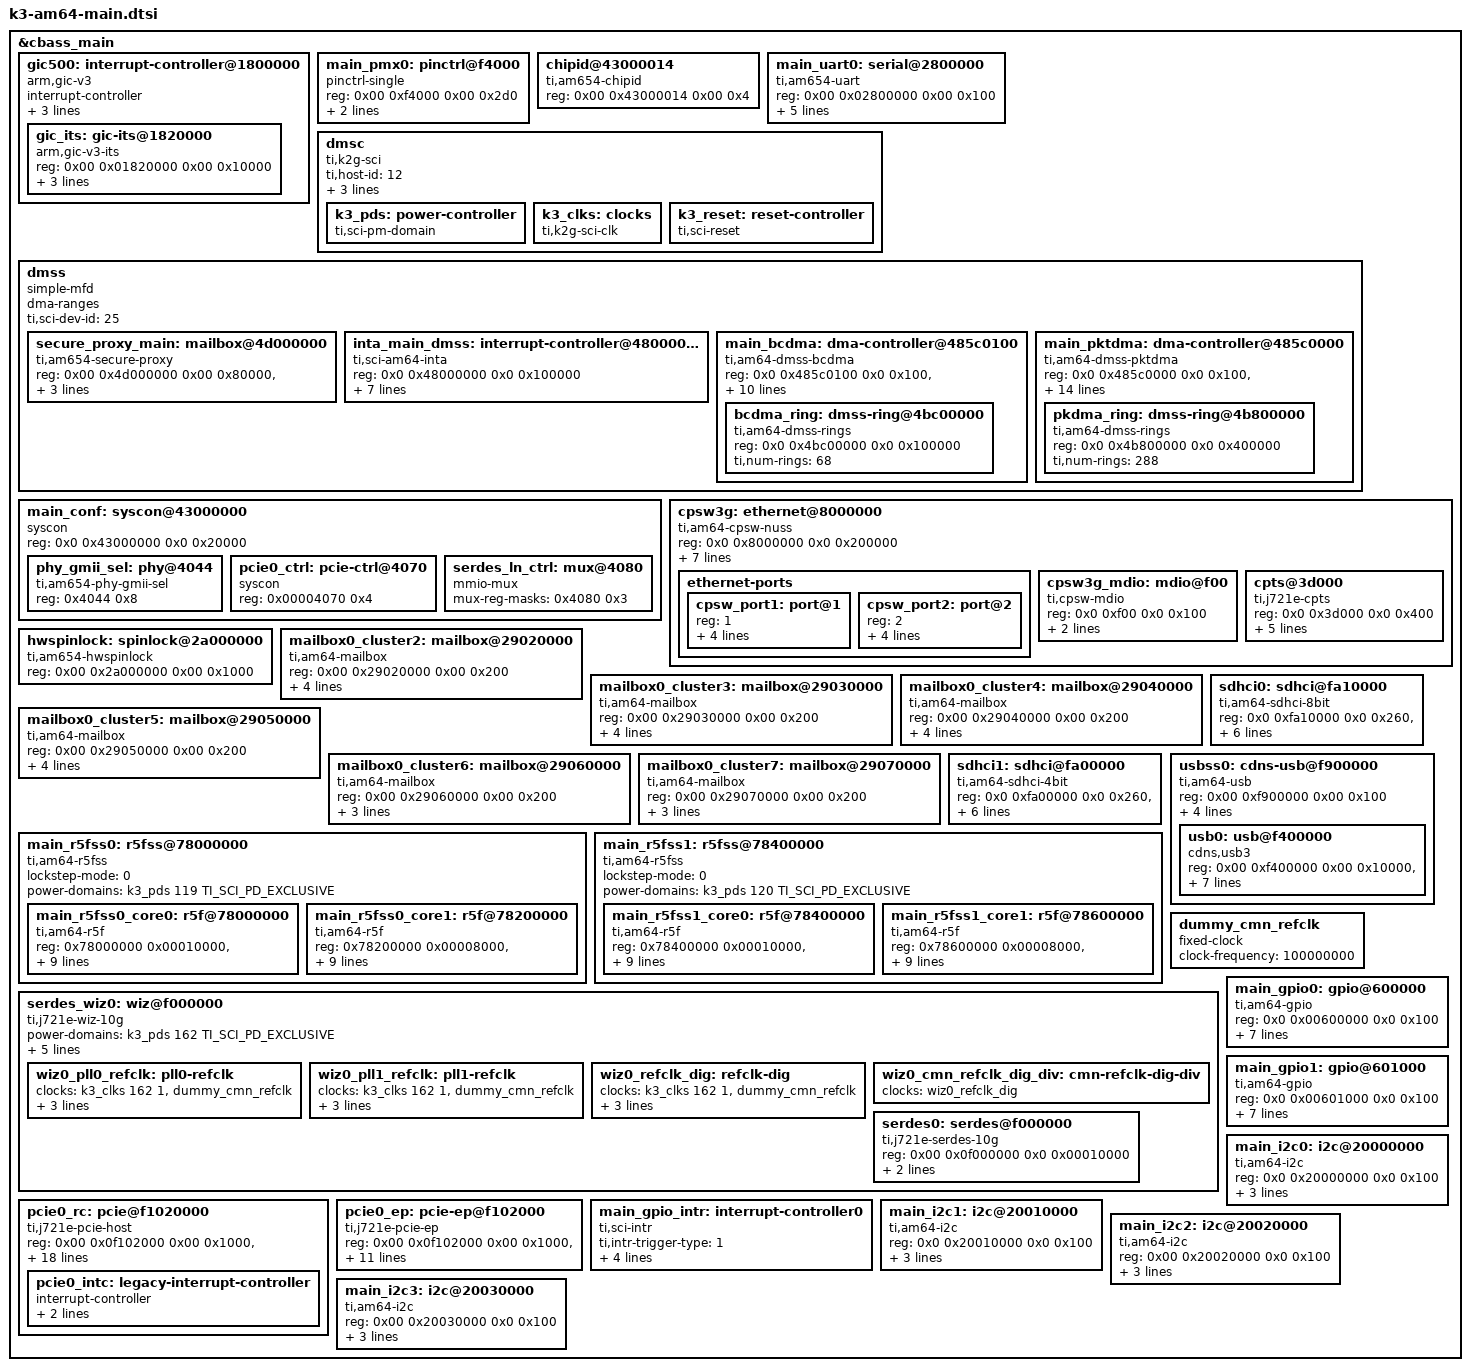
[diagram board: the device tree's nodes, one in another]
// SPDX-License-Identifier: GPL-2.0
/*
 * Device Tree Source for AM64 SoC Family Main Domain peripherals
 *
 * Copyright (C) 2019-2020 Texas Instruments Incorporated - https://www.ti.com/
 */

&cbass_main {
	gic500: interrupt-controller@1800000 {
		compatible = "arm,gic-v3";
		#address-cells = <2>;
		#size-cells = <2>;
		ranges;
		#interrupt-cells = <3>;
		interrupt-controller;
		reg = <0x00 0x01800000 0x00 0x10000>,	/* GICD */
		      <0x00 0x01840000 0x00 0xC0000>;	/* GICR */
		/*
		 * vcpumntirq:
		 * virtual CPU interface maintenance interrupt
		 */
		interrupts = <GIC_PPI 9 IRQ_TYPE_LEVEL_HIGH>;

		gic_its: gic-its@1820000 {
			compatible = "arm,gic-v3-its";
			reg = <0x00 0x01820000 0x00 0x10000>;
			socionext,synquacer-pre-its = <0x1000000 0x400000>;
			msi-controller;
			#msi-cells = <1>;
		};
	};

	main_pmx0: pinctrl@f4000 {
		compatible = "pinctrl-single";
		reg = <0x00 0xf4000 0x00 0x2d0>;
		#pinctrl-cells = <1>;
		pinctrl-single,register-width = <32>;
		pinctrl-single,function-mask = <0xffffffff>;
	};

	chipid@43000014 {
		compatible = "ti,am654-chipid";
		reg = <0x00 0x43000014 0x00 0x4>;
	};

	main_uart0: serial@2800000 {
		compatible = "ti,am654-uart";
		reg = <0x00 0x02800000 0x00 0x100>;
		reg-shift = <2>;
		reg-io-width = <4>;
		interrupts = <GIC_SPI 178 IRQ_TYPE_LEVEL_HIGH>;
		clock-frequency = <48000000>;
		current-speed = <115200>;
	};

	dmsc: dmsc {
		compatible = "ti,k2g-sci";
		ti,host-id = <12>;
		mbox-names = "rx", "tx";
		mboxes= <&secure_proxy_main 12>,
			<&secure_proxy_main 13>;

		k3_pds: power-controller {
			compatible = "ti,sci-pm-domain";
			#power-domain-cells = <2>;
		};

		k3_clks: clocks {
			compatible = "ti,k2g-sci-clk";
			#clock-cells = <2>;
		};

		k3_reset: reset-controller {
			compatible = "ti,sci-reset";
			#reset-cells = <2>;
		};
	};

	dmss {
		compatible = "simple-mfd";
		#address-cells = <2>;
		#size-cells = <2>;
		dma-ranges;
		ranges;

		ti,sci-dev-id = <25>;

		secure_proxy_main: mailbox@4d000000 {
			compatible = "ti,am654-secure-proxy";
			#mbox-cells = <1>;
			reg-names = "target_data", "rt", "scfg";
			reg = <0x00 0x4d000000 0x00 0x80000>,
			      <0x00 0x4a600000 0x00 0x80000>,
			      <0x00 0x4a400000 0x00 0x80000>;
			interrupt-names = "rx_012";
			interrupts = <GIC_SPI 34 IRQ_TYPE_LEVEL_HIGH>;
		};

		inta_main_dmss: interrupt-controller@48000000 {
			compatible = "ti,sci-am64-inta";
			reg = <0x0 0x48000000 0x0 0x100000>;
			interrupt-controller;
			interrupt-parent = <&gic500>;
			msi-controller;
			ti,sci = <&dmsc>;
			ti,sci-dev-id = <28>;
			ti,dev-ids-for-unmapped = <26>, <30>;
			ti,interrupt-ranges = <4 68 36>;
		};

		main_bcdma: dma-controller@485c0100 {
			compatible = "ti,am64-dmss-bcdma";
			#address-cells = <2>;
			#size-cells = <2>;
			ranges;

			reg =	<0x0 0x485c0100 0x0 0x100>,
				<0x0 0x4c000000 0x0 0x20000>,
				<0x0 0x4a820000 0x0 0x20000>,
				<0x0 0x4aa40000 0x0 0x20000>;
			reg-names = "gcfg", "bchanrt", "rchanrt", "tchanrt";
			msi-parent = <&inta_main_dmss>;
			#dma-cells = <2>;

			ti,sci = <&dmsc>;
			ti,sci-dev-id = <26>;
			ti,ringacc = <&bcdma_ring>;

			ti,sci-rm-range-bchan = <0x20>; /* BLOCK_COPY_CHAN */
			ti,sci-rm-range-rchan = <0x21>; /* SPLIT_TR_RX_CHAN */
			ti,sci-rm-range-tchan = <0x22>; /* SPLIT_TR_TX_CHAN */

			bcdma_ring: dmss-ring@4bc00000 {
				compatible = "ti,am64-dmss-rings";
				reg =	<0x0 0x4bc00000 0x0 0x100000>;
				reg-names = "rt";
				ti,num-rings = <68>;
			};
		};

		main_pktdma: dma-controller@485c0000 {
			compatible = "ti,am64-dmss-pktdma";
			#address-cells = <2>;
			#size-cells = <2>;
			ranges;

			reg =	<0x0 0x485c0000 0x0 0x100>,
				<0x0 0x4a800000 0x0 0x20000>,
				<0x0 0x4aa00000 0x0 0x40000>;
			reg-names = "gcfg", "rchanrt", "tchanrt";
			msi-parent = <&inta_main_dmss>;
			#dma-cells = <2>;

			ti,sci = <&dmsc>;
			ti,sci-dev-id = <30>;
			ti,ringacc = <&pkdma_ring>;

			ti,sci-rm-range-tchan = <0x23>, /* UNMAPPED_TX_CHAN */
						<0x24>, /* CPSW_TX_CHAN */
						<0x25>, /* SAUL_TX_0_CHAN */
						<0x26>, /* SAUL_TX_1_CHAN */
						<0x27>, /* ICSSG_0_TX_CHAN */
						<0x28>; /* ICSSG_1_TX_CHAN */
			ti,sci-rm-range-tflow = <0x10>, /* RING_UNMAPPED_TX_CHAN */
						<0x11>, /* RING_CPSW_TX_CHAN */
						<0x12>, /* RING_SAUL_TX_0_CHAN */
						<0x13>, /* RING_SAUL_TX_1_CHAN */
						<0x14>, /* RING_ICSSG_0_TX_CHAN */
						<0x15>; /* RING_ICSSG_1_TX_CHAN */
			ti,sci-rm-range-rchan = <0x29>, /* UNMAPPED_RX_CHAN */
						<0x2b>, /* CPSW_RX_CHAN */
						<0x2d>, /* SAUL_RX_0_CHAN */
						<0x2f>, /* SAUL_RX_1_CHAN */
						<0x31>, /* SAUL_RX_2_CHAN */
						<0x33>, /* SAUL_RX_3_CHAN */
						<0x35>, /* ICSSG_0_RX_CHAN */
						<0x37>; /* ICSSG_1_RX_CHAN */
			ti,sci-rm-range-rflow = <0x2a>, /* FLOW_UNMAPPED_RX_CHAN */
						<0x2c>, /* FLOW_CPSW_RX_CHAN */
						<0x2e>, /* FLOW_SAUL_RX_0/1_CHAN */
						<0x32>, /* FLOW_SAUL_RX_2/3_CHAN */
						<0x36>, /* FLOW_ICSSG_0_RX_CHAN */
						<0x38>; /* FLOW_ICSSG_1_RX_CHAN */

			pkdma_ring: dmss-ring@4b800000 {
				compatible = "ti,am64-dmss-rings";
				reg =	<0x0 0x4b800000 0x0 0x400000>;
				reg-names = "rt";
				ti,num-rings = <288>;
			};
		};
	};

	main_conf: syscon@43000000 {
		compatible = "syscon", "simple-mfd";
		reg = <0x0 0x43000000 0x0 0x20000>;
		#address-cells = <1>;
		#size-cells = <1>;
		ranges = <0x0 0x0 0x43000000 0x20000>;

		phy_gmii_sel: phy@4044 {
			compatible = "ti,am654-phy-gmii-sel";
			reg = <0x4044 0x8>;
			#phy-cells = <1>;
		};

		pcie0_ctrl: pcie-ctrl@4070 {
			compatible = "syscon";
			reg = <0x00004070 0x4>;
		};

		serdes_ln_ctrl: mux@4080 {
			compatible = "mmio-mux";
			#mux-control-cells = <1>;
			mux-reg-masks = <0x4080 0x3>; /* SERDES0 lane0 select */
		};
	};


	cpsw3g: ethernet@8000000 {
		compatible = "ti,am64-cpsw-nuss";
		#address-cells = <2>;
		#size-cells = <2>;
		reg = <0x0 0x8000000 0x0 0x200000>;
		reg-names = "cpsw_nuss";
		ranges = <0x0 0x0 0x0 0x8000000 0x0 0x200000>;
		clocks = <&k3_clks 13 0>;
		clock-names = "fck";
		power-domains = <&k3_pds 13 TI_SCI_PD_EXCLUSIVE>;

		dmas = <&main_pktdma 0xC500 0>,
		       <&main_pktdma 0xC501 0>,
		       <&main_pktdma 0xC502 0>,
		       <&main_pktdma 0xC503 0>,
		       <&main_pktdma 0xC504 0>,
		       <&main_pktdma 0xC505 0>,
		       <&main_pktdma 0xC506 0>,
		       <&main_pktdma 0xC507 0>,
		       <&main_pktdma 0x4500 0>;
		dma-names = "tx0", "tx1", "tx2", "tx3", "tx4", "tx5", "tx6",
			    "tx7", "rx";

		ethernet-ports {
			#address-cells = <1>;
			#size-cells = <0>;

			cpsw_port1: port@1 {
				reg = <1>;
				ti,mac-only;
				label = "port1";
				phys = <&phy_gmii_sel 1>;
				mac-address = [00 00 de ad be ef];
			};

			cpsw_port2: port@2 {
				reg = <2>;
				ti,mac-only;
				label = "port2";
				phys = <&phy_gmii_sel 2>;
				mac-address = [00 01 de ad be ef];
			};
		};

		cpsw3g_mdio: mdio@f00 {
			compatible = "ti,cpsw-mdio","ti,davinci_mdio";
			reg = <0x0 0xf00 0x0 0x100>;
			#address-cells = <1>;
			#size-cells = <0>;
			clocks = <&k3_clks 13 0>;
			clock-names = "fck";
			bus_freq = <1000000>;
		};

		cpts@3d000 {
			compatible = "ti,j721e-cpts";
			reg = <0x0 0x3d000 0x0 0x400>;
			clocks = <&k3_clks 13 1>;
			clock-names = "cpts";
			interrupts-extended = <&gic500 GIC_SPI 102 IRQ_TYPE_LEVEL_HIGH>;
			interrupt-names = "cpts";
			ti,cpts-ext-ts-inputs = <4>;
			ti,cpts-periodic-outputs = <2>;
		};
	};

	hwspinlock: spinlock@2a000000 {
		compatible = "ti,am654-hwspinlock";
		reg = <0x00 0x2a000000 0x00 0x1000>;
		#hwlock-cells = <1>;
	};

	mailbox0_cluster2: mailbox@29020000 {
		compatible = "ti,am64-mailbox";
		reg = <0x00 0x29020000 0x00 0x200>;
		interrupts = <GIC_SPI 80 IRQ_TYPE_LEVEL_HIGH>,
			     <GIC_SPI 81 IRQ_TYPE_LEVEL_HIGH>;
		#mbox-cells = <1>;
		ti,mbox-num-users = <4>;
		ti,mbox-num-fifos = <16>;
	};

	mailbox0_cluster3: mailbox@29030000 {
		compatible = "ti,am64-mailbox";
		reg = <0x00 0x29030000 0x00 0x200>;
		interrupts = <GIC_SPI 82 IRQ_TYPE_LEVEL_HIGH>,
			     <GIC_SPI 83 IRQ_TYPE_LEVEL_HIGH>;
		#mbox-cells = <1>;
		ti,mbox-num-users = <4>;
		ti,mbox-num-fifos = <16>;
	};

	mailbox0_cluster4: mailbox@29040000 {
		compatible = "ti,am64-mailbox";
		reg = <0x00 0x29040000 0x00 0x200>;
		interrupts = <GIC_SPI 84 IRQ_TYPE_LEVEL_HIGH>,
			     <GIC_SPI 85 IRQ_TYPE_LEVEL_HIGH>;
		#mbox-cells = <1>;
		ti,mbox-num-users = <4>;
		ti,mbox-num-fifos = <16>;
	};

	mailbox0_cluster5: mailbox@29050000 {
		compatible = "ti,am64-mailbox";
		reg = <0x00 0x29050000 0x00 0x200>;
		interrupts = <GIC_SPI 86 IRQ_TYPE_LEVEL_HIGH>,
			     <GIC_SPI 87 IRQ_TYPE_LEVEL_HIGH>;
		#mbox-cells = <1>;
		ti,mbox-num-users = <4>;
		ti,mbox-num-fifos = <16>;
	};

	mailbox0_cluster6: mailbox@29060000 {
		compatible = "ti,am64-mailbox";
		reg = <0x00 0x29060000 0x00 0x200>;
		interrupts = <GIC_SPI 76 IRQ_TYPE_LEVEL_HIGH>;
		#mbox-cells = <1>;
		ti,mbox-num-users = <4>;
		ti,mbox-num-fifos = <16>;
	};

	mailbox0_cluster7: mailbox@29070000 {
		compatible = "ti,am64-mailbox";
		reg = <0x00 0x29070000 0x00 0x200>;
		interrupts = <GIC_SPI 77 IRQ_TYPE_LEVEL_HIGH>;
		#mbox-cells = <1>;
		ti,mbox-num-users = <4>;
		ti,mbox-num-fifos = <16>;
	};

	sdhci0: sdhci@fa10000 {
		compatible = "ti,am64-sdhci-8bit";
		reg = <0x0 0xfa10000 0x0 0x260>, <0x0 0xfa18000 0x0 0x134>;
		power-domains = <&k3_pds 57 TI_SCI_PD_EXCLUSIVE>;
		clocks = <&k3_clks 57 0>, <&k3_clks 57 1>;
		clock-names = "clk_ahb", "clk_xin";
		interrupts = <GIC_SPI 133 IRQ_TYPE_LEVEL_HIGH>;
		ti,trm-icp = <0x2>;
		ti,otap-del-sel-legacy = <0x0>;
	};

	sdhci1: sdhci@fa00000 {
		compatible = "ti,am64-sdhci-4bit";
		reg = <0x0 0xfa00000 0x0 0x260>, <0x0 0xfa08000 0x0 0x134>;
		power-domains = <&k3_pds 58 TI_SCI_PD_EXCLUSIVE>;
		clocks = <&k3_clks 58 3>, <&k3_clks 58 4>;
		clock-names = "clk_ahb", "clk_xin";
		interrupts = <GIC_SPI 134 IRQ_TYPE_LEVEL_HIGH>;
		ti,otap-del-sel-legacy = <0x0>;
		ti,trm-icp = <0x2>;
	};

	main_r5fss0: r5fss@78000000 {
		compatible = "ti,am64-r5fss";
		lockstep-mode = <0>;
		#address-cells = <1>;
		#size-cells = <1>;
		ranges = <0x78000000 0x00 0x78000000 0x10000>,
			 <0x78100000 0x00 0x78100000 0x10000>,
			 <0x78200000 0x00 0x78200000 0x08000>,
			 <0x78300000 0x00 0x78300000 0x08000>;
		power-domains = <&k3_pds 119 TI_SCI_PD_EXCLUSIVE>;

		main_r5fss0_core0: r5f@78000000 {
			compatible = "ti,am64-r5f";
			reg = <0x78000000 0x00010000>,
			      <0x78100000 0x00010000>;
			reg-names = "atcm", "btcm";
			ti,sci = <&dmsc>;
			ti,sci-dev-id = <121>;
			ti,sci-proc-ids = <0x01 0xff>;
			resets = <&k3_reset 121 1>;
			firmware-name = "am64-main-r5f0_0-fw";
			atcm-enable = <1>;
			btcm-enable = <1>;
			loczrama = <1>;
		};

		main_r5fss0_core1: r5f@78200000 {
			compatible = "ti,am64-r5f";
			reg = <0x78200000 0x00008000>,
			      <0x78300000 0x00008000>;
			reg-names = "atcm", "btcm";
			ti,sci = <&dmsc>;
			ti,sci-dev-id = <122>;
			ti,sci-proc-ids = <0x02 0xff>;
			resets = <&k3_reset 122 1>;
			firmware-name = "am64-main-r5f0_1-fw";
			atcm-enable = <1>;
			btcm-enable = <1>;
			loczrama = <1>;
		};
	};

	main_r5fss1: r5fss@78400000 {
		compatible = "ti,am64-r5fss";
		lockstep-mode = <0>;
		#address-cells = <1>;
		#size-cells = <1>;
		ranges = <0x78400000 0x00 0x78400000 0x10000>,
			 <0x78500000 0x00 0x78500000 0x10000>,
			 <0x78600000 0x00 0x78600000 0x08000>,
			 <0x78700000 0x00 0x78700000 0x08000>;
		power-domains = <&k3_pds 120 TI_SCI_PD_EXCLUSIVE>;

		main_r5fss1_core0: r5f@78400000 {
			compatible = "ti,am64-r5f";
			reg = <0x78400000 0x00010000>,
			      <0x78500000 0x00010000>;
			reg-names = "atcm", "btcm";
			ti,sci = <&dmsc>;
			ti,sci-dev-id = <123>;
			ti,sci-proc-ids = <0x06 0xff>;
			resets = <&k3_reset 123 1>;
			firmware-name = "am64-main-r5f1_0-fw";
			atcm-enable = <1>;
			btcm-enable = <1>;
			loczrama = <1>;
		};

		main_r5fss1_core1: r5f@78600000 {
			compatible = "ti,am64-r5f";
			reg = <0x78600000 0x00008000>,
			      <0x78700000 0x00008000>;
			reg-names = "atcm", "btcm";
			ti,sci = <&dmsc>;
			ti,sci-dev-id = <124>;
			ti,sci-proc-ids = <0x07 0xff>;
			resets = <&k3_reset 124 1>;
			firmware-name = "am64-main-r5f1_1-fw";
			atcm-enable = <1>;
			btcm-enable = <1>;
			loczrama = <1>;
		};
	};

	usbss0: cdns-usb@f900000{
		compatible = "ti,am64-usb", "ti,j721e-usb";
		reg = <0x00 0xf900000 0x00 0x100>;
		power-domains = <&k3_pds 161 TI_SCI_PD_EXCLUSIVE>;
		clocks = <&k3_clks 161 9>, <&k3_clks 161 1>;
		clock-names = "ref", "lpm";
		assigned-clocks = <&k3_clks 161 9>; /* USB2_REFCLK */
		assigned-clock-parents = <&k3_clks 161 10>; /* HF0SC0 */
		#address-cells = <2>;
		#size-cells = <2>;
		ranges;
		usb0: usb@f400000{
			compatible = "cdns,usb3";
			reg = <0x00 0xf400000 0x00 0x10000>,
			      <0x00 0xf410000 0x00 0x10000>,
			      <0x00 0xf420000 0x00 0x10000>;
			reg-names = "otg",
				    "xhci",
				    "dev";
			interrupts = <GIC_SPI 188 IRQ_TYPE_LEVEL_HIGH>, /* irq.0 */
				     <GIC_SPI 194 IRQ_TYPE_LEVEL_HIGH>, /* irq.6 */
				     <GIC_SPI 196 IRQ_TYPE_LEVEL_HIGH>; /* otgirq */
			interrupt-names = "host",
					  "peripheral",
					  "otg";
			maximum-speed = "super-speed";
			dr_mode = "otg";
		};
	};

	dummy_cmn_refclk: dummy_cmn_refclk {
		#clock-cells = <0>;
		compatible = "fixed-clock";
		clock-frequency = <100000000>;
	};

	serdes_wiz0: wiz@f000000 {
		compatible = "ti,j721e-wiz-10g";
		#address-cells = <2>;
		#size-cells = <2>;
		power-domains = <&k3_pds 162 TI_SCI_PD_EXCLUSIVE>;
		clocks = <&k3_clks 162 0>, <&k3_clks 162 1>, <&dummy_cmn_refclk>;
		clock-names = "fck", "core_ref_clk", "ext_ref_clk";
		num-lanes = <1>;
		#reset-cells = <1>;
		ranges;

		assigned-clocks = <&k3_clks 162 1>;
		assigned-clock-parents = <&k3_clks 162 5>;

		wiz0_pll0_refclk: pll0-refclk {
			clocks = <&k3_clks 162 1>, <&dummy_cmn_refclk>;
			clock-output-names = "wiz0_pll0_refclk";
			#clock-cells = <0>;
			assigned-clocks = <&wiz0_pll0_refclk>;
			assigned-clock-parents = <&k3_clks 162 1>;
		};

		wiz0_pll1_refclk: pll1-refclk {
			clocks = <&k3_clks 162 1>, <&dummy_cmn_refclk>;
			clock-output-names = "wiz0_pll1_refclk";
			#clock-cells = <0>;
			assigned-clocks = <&wiz0_pll1_refclk>;
			assigned-clock-parents = <&k3_clks 162 1>;
		};

		wiz0_refclk_dig: refclk-dig {
			clocks = <&k3_clks 162 1>, <&dummy_cmn_refclk>;
			clock-output-names = "wiz0_refclk_dig";
			#clock-cells = <0>;
			assigned-clocks = <&wiz0_refclk_dig>;
			assigned-clock-parents = <&k3_clks 162 1>;
		};

		wiz0_cmn_refclk_dig_div: cmn-refclk-dig-div {
			clocks = <&wiz0_refclk_dig>;
			#clock-cells = <0>;
		};

		serdes0: serdes@f000000 {
			compatible = "ti,j721e-serdes-10g";
			reg = <0x00 0x0f000000 0x0 0x00010000>;
			resets = <&serdes_wiz0 0>;
			reset-names = "torrent_reset";
			clocks = <&wiz0_pll0_refclk>;
			clock-names = "refclk";
			#address-cells = <1>;
			#size-cells = <0>;
		};
	};

	pcie0_rc: pcie@f1020000 {
		compatible = "ti,j721e-pcie-host";
		reg = <0x00 0x0f102000 0x00 0x1000>,
		      <0x00 0x0f100000 0x00 0x400>,
		      <0x00 0x0d000000 0x00 0x00800000>,
		      <0x00 0x68000000 0x00 0x00001000>;
		reg-names = "intd_cfg", "user_cfg", "reg", "cfg";
		ti,syscon-pcie-ctrl = <&pcie0_ctrl>;
		max-link-speed = <2>;
		num-lanes = <1>;
		power-domains = <&k3_pds 114 TI_SCI_PD_EXCLUSIVE>;
		clocks = <&k3_clks 114 0>;
		clock-names = "fck";
		#address-cells = <3>;
		#size-cells = <2>;
		bus-range = <0x0 0xf>;
		cdns,max-outbound-regions = <32>;
		cdns,no-bar-match-nbits = <64>;
		vendor-id = /bits/ 16 <0x104c>;
		device-id = /bits/ 16 <0xb010>;
		msi-map = <0x0 &gic_its 0x0 0x10000>;
		ranges = <0x01000000 0x00 0x68001000  0x00 0x68001000  0x00 0x0010000>,
			 <0x02000000 0x00 0x68011000  0x00 0x68011000  0x00 0x7fef000>;
		#interrupt-cells = <1>;
		interrupt-map-mask = <0 0 0 7>;
		interrupt-map = <0 0 0 1 &pcie0_intc 0>, /* INT A */
				<0 0 0 2 &pcie0_intc 0>, /* INT B */
				<0 0 0 3 &pcie0_intc 0>, /* INT C */
				<0 0 0 4 &pcie0_intc 0>; /* INT D */

		pcie0_intc: legacy-interrupt-controller {
			interrupt-controller;
			#interrupt-cells = <1>;
			interrupt-parent = <&gic500>;
			interrupts = <GIC_SPI 202 IRQ_TYPE_EDGE_RISING>;
		};
	};

	pcie0_ep: pcie-ep@f102000 {
		compatible = "ti,j721e-pcie-ep";
		reg = <0x00 0x0f102000 0x00 0x1000>,
		      <0x00 0x0f100000 0x00 0x400>,
		      <0x00 0x0d000000 0x00 0x00800000>,
		      <0x00 0x68000000 0x00 0x08000000>;
		reg-names = "intd_cfg", "user_cfg", "reg", "mem";
		ti,syscon-pcie-ctrl = <&pcie0_ctrl>;
		max-link-speed = <2>;
		num-lanes = <1>;
		power-domains = <&k3_pds 114 TI_SCI_PD_EXCLUSIVE>;
		clocks = <&k3_clks 114 0>;
		clock-names = "fck";
		cdns,max-outbound-regions = <32>;
		max-functions = /bits/ 8 <6>;
		max-virtual-functions = /bits/ 16 <4 4 4 4 0 0>;
	};

	main_gpio_intr: interrupt-controller0 {
		compatible = "ti,sci-intr";
		ti,intr-trigger-type = <1>;
		interrupt-controller;
		#interrupt-cells = <1>;
		ti,sci = <&dmsc>;
		ti,sci-dev-id = <3>;
		ti,interrupt-ranges = <0 32 16>;
	};

	main_gpio0: gpio@600000 {
		compatible = "ti,am64-gpio", "ti,keystone-gpio";
		reg = <0x0 0x00600000 0x0 0x100>;
		gpio-controller;
		#gpio-cells = <2>;
		interrupt-parent = <&main_gpio_intr>;
		interrupts = <190>, <191>, <192>,
			     <193>, <194>, <195>;
		interrupt-controller;
		#interrupt-cells = <2>;
		ti,ngpio = <87>;
		ti,davinci-gpio-unbanked = <0>;
		clocks = <&k3_clks 77 0>;
		clock-names = "gpio";
	};

	main_gpio1: gpio@601000 {
		compatible = "ti,am64-gpio", "ti,keystone-gpio";
		reg = <0x0 0x00601000 0x0 0x100>;
		gpio-controller;
		#gpio-cells = <2>;
		interrupt-parent = <&main_gpio_intr>;
		interrupts = <180>, <181>, <182>,
			     <183>, <184>, <185>;
		interrupt-controller;
		#interrupt-cells = <2>;
		ti,ngpio = <88>;
		ti,davinci-gpio-unbanked = <0>;
		clocks = <&k3_clks 78 0>;
		clock-names = "gpio";
	};

	main_i2c0: i2c@20000000 {
		compatible = "ti,am64-i2c", "ti,omap4-i2c";
		reg = <0x0 0x20000000 0x0 0x100>;
		interrupts = <GIC_SPI 161 IRQ_TYPE_LEVEL_HIGH>;
		#address-cells = <1>;
		#size-cells = <0>;
		clock-names = "fck";
		clocks = <&k3_clks 102 2>;
		power-domains = <&k3_pds 102 TI_SCI_PD_EXCLUSIVE>;
	};

	main_i2c1: i2c@20010000 {
		compatible = "ti,am64-i2c", "ti,omap4-i2c";
		reg = <0x0 0x20010000 0x0 0x100>;
		interrupts = <GIC_SPI 162 IRQ_TYPE_LEVEL_HIGH>;
		#address-cells = <1>;
		#size-cells = <0>;
		clock-names = "fck";
		clocks = <&k3_clks 103 2>;
		power-domains = <&k3_pds 103 TI_SCI_PD_EXCLUSIVE>;
	};

	main_i2c2: i2c@20020000 {
		compatible = "ti,am64-i2c", "ti,omap4-i2c";
		reg = <0x00 0x20020000 0x0 0x100>;
		interrupts = <GIC_SPI 163 IRQ_TYPE_LEVEL_HIGH>;
		#address-cells = <1>;
		#size-cells = <0>;
		clock-names = "fck";
		clocks = <&k3_clks 104 2>;
		power-domains = <&k3_pds 104 TI_SCI_PD_EXCLUSIVE>;
	};

	main_i2c3: i2c@20030000 {
		compatible = "ti,am64-i2c", "ti,omap4-i2c";
		reg = <0x00 0x20030000 0x0 0x100>;
		interrupts = <GIC_SPI 164 IRQ_TYPE_LEVEL_HIGH>;
		#address-cells = <1>;
		#size-cells = <0>;
		clock-names = "fck";
		clocks = <&k3_clks 105 2>;
		power-domains = <&k3_pds 105 TI_SCI_PD_EXCLUSIVE>;
	};
};
